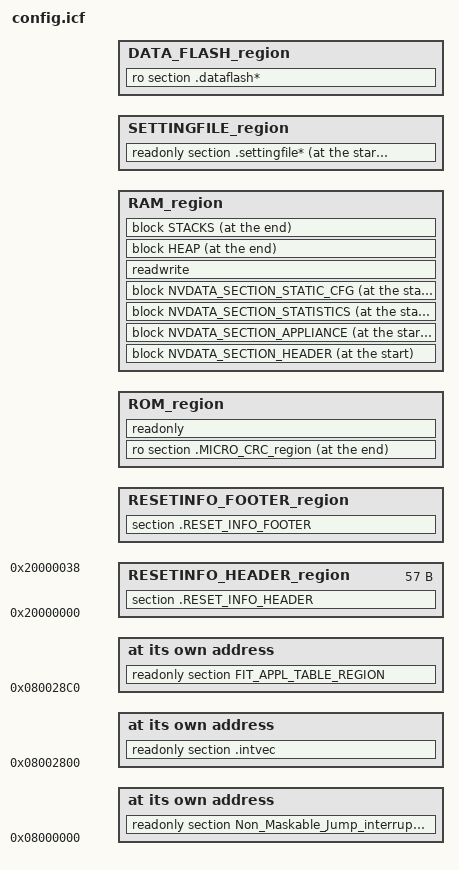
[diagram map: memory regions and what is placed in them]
/**
 *  @file       Config.icf       
 *
 *  @brief      This file contains the linker configurations related to STM32G0x micro
 *
 *  @details    The Flash Memory page size is 0x800 bytes.
 *              Size of SETTINGFILE_SIZE size and IAP_SIZE size shall be multiple of 0x800
 *              
 *              The Data Flash Memory page size is 0x800 bytes
 *
 *  @copyright  Copyright 2021-$Date: 2021/06/16 14:15:12EDT $. Whirlpool Corporation. All rights reserved - CONFIDENTIAL
 */
//---------------------------------------------------------------------------------------------------------------------

/*=======================================================================================================*/
/* Memory Map for STM32G0x Micro-controller. Only modify the value as per the micro specification
/*-------------------------------------------------------------------------------------------------------*/

/*-Memory Regions-*/
define exported symbol FLASH_TOTAL_SIZE                     = 0x80000;      // 512KB Total Flash
define exported symbol RAM_TOTAL_SIZE                       = 0x24000;      // 144KB Total RAM
define exported symbol SETTINGFILE_SIZE                     = 0x4800;       // Shall be multiple of 0x800
define exported symbol DATAFLASH_SIZE                       = 0x1800;       // Shall be multiple of 0x800.

/*-Sizes-*/
define exported symbol __ICFEDIT_size_cstack__              = 0x400;
define exported symbol __ICFEDIT_size_heap__                = 0x4;

/*------------ End of Memory Map ------------------------------------------------------------------------*/


/*=======================================================================================================*/
/* FIT Table Offset - Default value (0xC0) - Do not change                                               */
/*-------------------------------------------------------------------------------------------------------*/
define exported symbol FIT_TABLE_OFFSET                                     = 0xC0;

/*------------ End of FIT Table Offset ------------------------------------------------------------------*/




/*=======================================================================================================*/
/* Mapping the sections - Do not change
/*-------------------------------------------------------------------------------------------------------*/

/*-Do not change the size */
define exported symbol IAP_SIZE                                 = 0x2800;   // For Nucleus Framework its mandatory to have the IAP
define exported symbol FLASH_START_ADDRESS					    = 0x08000000;

define exported symbol __ICFEDIT_INTERRUPT_TABLE_start__        = FLASH_START_ADDRESS + IAP_SIZE;

define exported symbol __ICFEDIT_region_ROM_start__             = __ICFEDIT_INTERRUPT_TABLE_start__;
define exported symbol __ICFEDIT_region_ROM_end__               = (__ICFEDIT_region_ROM_start__ + FLASH_TOTAL_SIZE -  IAP_SIZE - SETTINGFILE_SIZE - DATAFLASH_SIZE - 1);

define exported symbol __ICFEDIT_region_RAM_start__             = 0x20000000;
define exported symbol __ICFEDIT_region_RAM_end__               = (__ICFEDIT_region_RAM_start__ + RAM_TOTAL_SIZE - 1);

define exported symbol __SettingFile_X_Start__                  = (__ICFEDIT_region_ROM_end__ + 1);
define exported symbol __SettingFile_X_End__                    = __SettingFile_X_Start__+ SETTINGFILE_SIZE - 1;

define exported symbol __DataFlash_Start__                      = __SettingFile_X_End__ + 1;
define exported symbol __DataFlash_End__                        = (__DataFlash_Start__ + DATAFLASH_SIZE - 1);

define exported symbol __ICFEDIT_size_stack_bottom__            = 0x10;
define exported symbol __ICFEDIT_size_stack_top__               = 0x10;

/*-Do not change the size */
define memory mem with size = 4G;

/*------------ End of Memory Map ------------------------------------------------------------------------*/





/*=======================================================================================================*/
/* RESET Information region - Do not modify
/*-------------------------------------------------------------------------------------------------------*/
define symbol RESETINFO_HEADER_SIZE             = 56;
define symbol RESETINFO_HEADER_START            = __ICFEDIT_region_RAM_start__;
define symbol RESETINFO_HEADER_END              = RESETINFO_HEADER_START + RESETINFO_HEADER_SIZE;

define symbol RESETINFO_FOOTER_SIZE             = 44;
define symbol RESETINFO_FOOTER_START            = __ICFEDIT_region_RAM_end__ - RESETINFO_FOOTER_SIZE;
define symbol RESETINFO_FOOTER_END              = __ICFEDIT_region_RAM_end__;

define symbol APPLICATION_RAM_region_start      = RESETINFO_HEADER_END;
define symbol APPLICATION_RAM_region_end        = RESETINFO_FOOTER_START;

define region RESETINFO_HEADER_region           = mem:[from RESETINFO_HEADER_START         to RESETINFO_HEADER_END  ];
define region RESETINFO_FOOTER_region           = mem:[from RESETINFO_FOOTER_START         to RESETINFO_FOOTER_END  ];

do not initialize  { section .RESET_INFO_HEADER, section .RESET_INFO_FOOTER};

place in RESETINFO_HEADER_region   { section .RESET_INFO_HEADER  };
place in RESETINFO_FOOTER_region   { section .RESET_INFO_FOOTER  };

/*------------ End of RESET Information region ----------------------------------------------------------*/





/*=======================================================================================================*/
/* Memory region allocation
/*-------------------------------------------------------------------------------------------------------*/
define region ROM_region                = mem:[from __ICFEDIT_region_ROM_start__   to __ICFEDIT_region_ROM_end__];
define region RAM_region                = mem:[from APPLICATION_RAM_region_start   to APPLICATION_RAM_region_end];

define block CSTACK                     with alignment = 8, size = __ICFEDIT_size_cstack__   { };
define block HEAP                       with alignment = 8, size = __ICFEDIT_size_heap__     { };

define block INTERRUPT_STACK            with size = 0 { };
define block SYSTEM_STACK               { block CSTACK };

define block STACK_OVERFLOW_SIGNATURE   with alignment = 4, size = 0x10{};
define block STACK_UNDERFLOW_SIGNATURE  with alignment = 4, size = 0x10{};

define block TASKS_STACK   with alignment = 4, fixed order { section TASKS_STACK_SIG_BEFORE_THREADS,
                                                             section TASKS_STACK_MAIN_THREAD,
                                                             section TASKS_STACK_SIG_BETWEEN_THREADS_1,
                                                             section TASKS_STACK_APPMGR_THREAD,
                                                             section TASKS_STACK_SIG_BETWEEN_THREADS_2,
                                                             section TASKS_STACK_BACKGROUND_THREAD,
                                                             section TASKS_STACK_SIG_BETWEEN_THREADS_3,
                                                             section TASKS_STACK_COMMUNICATION_THREAD,
                                                             section TASKS_STACK_SIG_BETWEEN_THREADS_4,
                                                             section TASKS_STACK_FASTAPPMGR_THREAD,
                                                             section TASKS_STACK_SIG_BETWEEN_THREADS_5,
                                                             section TASKS_STACK_PROGRAMMINGASYNCH_THREAD,
                                                             section TASKS_STACK_SIG_AFTER_THREADS };

define block STACKS                     with alignment = 4, fixed order
                                        {   block STACK_OVERFLOW_SIGNATURE,
                                            block SYSTEM_STACK,
                                            block TASKS_STACK,
                                            block INTERRUPT_STACK,
                                            block STACK_UNDERFLOW_SIGNATURE,
                                        };

/*------------ End of memory region allocation ---------------------------------------------------------*/





/*=======================================================================================================*/
/* Setting file Configuration - Do Not Modify
/*-------------------------------------------------------------------------------------------------------*/
define exported symbol __SetingFile_Start       = __SettingFile_X_Start__;
define exported symbol __SetingFile_Size        = SETTINGFILE_SIZE;
define exported symbol __SetingFile_End         = __SettingFile_X_Start__+__SetingFile_Size;
define exported symbol __RAM_Start              = __ICFEDIT_region_RAM_start__;
define exported symbol __RAM_Size               = (__ICFEDIT_region_RAM_end__ - __ICFEDIT_region_RAM_start__);
define exported symbol __RAM_End                = __ICFEDIT_region_RAM_end__;

define region SETTINGFILE_region = mem:[from __SettingFile_X_Start__ to (__SettingFile_X_Start__+__SetingFile_Size-1)];
place at start of SETTINGFILE_region       { readonly section .settingfile* };

/*------------ End of Setting file Configuration ---------------------------------------------------------*/





/*=======================================================================================================*/
/* NVData Configuration
/*-------------------------------------------------------------------------------------------------------*/
 define exported symbol __DataFlash_Start       =__DataFlash_Start__; 
 define exported symbol __DataFlash_End         =__DataFlash_End__;

 define region DATA_FLASH_region = mem:[from __DataFlash_Start to __DataFlash_End];
 "DATAFLASH":place in DATA_FLASH_region         { ro section .dataflash* };
define block NVDATA_SECTION_HEADER              { rw section _header_segment };
define block NVDATA_SECTION_APPLIANCE           { rw section _appliance_segment };
define block NVDATA_SECTION_STATISTICS          { rw section _statistics_segment };
define block NVDATA_SECTION_STATIC_CFG          { rw section _static_cfg_segment };

place at start of   RAM_region                  { block NVDATA_SECTION_HEADER,
                                                  block  NVDATA_SECTION_APPLIANCE,
                                                  block  NVDATA_SECTION_STATISTICS,
                                                  block NVDATA_SECTION_STATIC_CFG };

/*------------ End of NVData Configuration ---------------------------------------------------------------*/





/*=======================================================================================================*/
/* ClassB-Configuration - Do not modify
/*-------------------------------------------------------------------------------------------------------*/
define exported symbol MICRO_FLASH_START        = __ICFEDIT_region_ROM_start__;
define exported symbol MICRO_FLASH_END          = __ICFEDIT_region_ROM_end__ - 4;

/* FLASH CRC checksum region on the ROM*/
place at end of ROM_region { ro section .MICRO_CRC_region };

/*------------ End of ClassB Configuration -------------------------------------------------------------*/





/*=======================================================================================================*/
/* IAP (In-Application Programming) configuration for Application project - Do not modify
/*-------------------------------------------------------------------------------------------------------*/
define symbol ___NON_MASKABLE_JUMP_INTERRUPT_TABLE_start__  = FLASH_START_ADDRESS; 
place at address mem:___NON_MASKABLE_JUMP_INTERRUPT_TABLE_start__ { readonly section Non_Maskable_Jump_interrupt_table };

define exported symbol APPL_BLOCK_1_START       = __ICFEDIT_region_ROM_start__;
define exported symbol APPL_BLOCK_1_END         = __ICFEDIT_region_ROM_end__ - 4;


/* This address is shared with the IAP Software */
/* Edit only if the FIT Table start address is different then the below */
define symbol __FIT_APPLICATION_TABLE_start__   = __ICFEDIT_INTERRUPT_TABLE_start__ + FIT_TABLE_OFFSET;
place at address mem:__FIT_APPLICATION_TABLE_start__    { readonly section FIT_APPL_TABLE_REGION };


// Location of IAP W Part number stored in the IAP area
// -16 is due to 10 bytes from W Part, 4 bytes from Crc32 and 2 bytes as for alignment
define exported symbol IAP_WPART_NUMBER           			= FLASH_START_ADDRESS + IAP_SIZE - 16;    

/*------------ End of IAP Configuration       ----------------------------------------------------------*/






/*=======================================================================================================*/
/* Placing of the memory
/*-------------------------------------------------------------------------------------------------------*/

initialize by copy { readwrite };
do not initialize  { section .noinit};

place at address mem:__ICFEDIT_INTERRUPT_TABLE_start__ { readonly section .intvec };

place in ROM_region   { readonly };
place in RAM_region   { readwrite};

// The Heap and Stack memory shall be placed at the end of the RAM memory and before the reset signature
// IAP uses the stack memory for code execution and this stack memory shall not be overlap with the data memory used by the application. 
// If the Stack and Heap memory's are placed at the end of the RAM then it will never overwrite the Data memory of the application
place at end of RAM_region                                             { block HEAP,
                                                                         block STACKS };

 /*------------ End of memory placing       ----------------------------------------------------------*/
